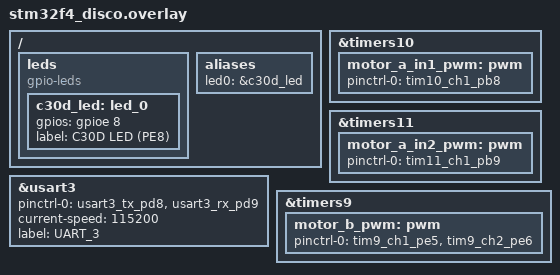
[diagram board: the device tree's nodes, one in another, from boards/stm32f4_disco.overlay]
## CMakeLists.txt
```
cmake_minimum_required(VERSION 3.20.0)

list(APPEND ZEPHYR_EXTRA_MODULES ${CMAKE_CURRENT_SOURCE_DIR}/../micro_ros_zephyr_module/modules/libmicroros)

find_package(Zephyr REQUIRED HINTS $ENV{ZEPHYR_BASE})
project(mdp_stm32_app)

target_sources(app PRIVATE
    src/main.c
    src/motor.c
)
```

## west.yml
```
manifest:
  remotes:
    - name: zephyrproject-rtos
      url-base: https://github.com/zephyrproject-rtos
    - name: micro-ROS
      url-base: https://github.com/micro-ROS

  projects:
    - name: zephyr
      remote: zephyrproject-rtos
      revision: v4.0.0
      import:
        name-allowlist:
          - cmsis          # ARM Cortex core headers
          - hal_stm32      # ST hardware abstraction (STM32F407 drivers/pinctrl/clock)
          - picolibc       # Small C library
          - segger         # SEGGER RTT debug print over ST-LINK
    - name: micro_ros_zephyr_module
      remote: micro-ROS
      revision: 229ffc0e131ee7942db3bb2e731fb8851583bb25

  self:
    path: .
```

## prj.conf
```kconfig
# GPIO & PWM Drivers
CONFIG_GPIO=y
CONFIG_PWM=y

# SEGGER RTT Console & Logging (Debug print via ST-LINK)
CONFIG_USE_SEGGER_RTT=y
CONFIG_RTT_CONSOLE=y
CONFIG_CONSOLE=y
CONFIG_LOG=y
CONFIG_LOG_BACKEND_RTT=y
CONFIG_LOG_MODE_IMMEDIATE=y

# Serial Drivers
CONFIG_SERIAL=y
CONFIG_UART_INTERRUPT_DRIVEN=y

# POSIX & Memory Defaults
CONFIG_POSIX_API=y
CONFIG_HEAP_MEM_POOL_SIZE=16384
CONFIG_MAIN_STACK_SIZE=4096
```

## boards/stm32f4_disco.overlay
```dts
/*
 * Devicetree overlay for WHEELTEC C30D (Revision 2.1) Control Board
 * Based on STM32F407VET6 MCU and AT8236 motor drivers.
 */

/ {
	leds {
		compatible = "gpio-leds";
		c30d_led: led_0 {
			gpios = <&gpioe 8 GPIO_ACTIVE_HIGH>;
			label = "C30D LED (PE8)";
		};
	};

	aliases {
		led0 = &c30d_led;
	};
};

/*
 * USART3 -> C30D USB-serial #3 (USB Type-C) on PD8 (TX3) and PD9 (RX3).
 * Connected via CH9102F USB-to-UART chip.
 */
&usart3 {
	pinctrl-0 = <&usart3_tx_pd8 &usart3_rx_pd9>;
	pinctrl-names = "default";
	current-speed = <115200>;
	status = "okay";
	label = "UART_3";
};

/*
 * AT8236 Dual H-Bridge Motor Drivers (PWM Output Timers)
 *
 * Motor A (Rear Left):  PB8 (TIM10_CH1) / PB9 (TIM11_CH1)
 * Motor B (Rear Right): PE5 (TIM9_CH1)  / PE6 (TIM9_CH2)
 * Motor C & D:          PE9, PE11, PE13, PE14 (TIM1)
 */
&timers10 {
	status = "okay";
	motor_a_in1_pwm: pwm {
		status = "okay";
		pinctrl-0 = <&tim10_ch1_pb8>;
		pinctrl-names = "default";
	};
};

&timers11 {
	status = "okay";
	motor_a_in2_pwm: pwm {
		status = "okay";
		pinctrl-0 = <&tim11_ch1_pb9>;
		pinctrl-names = "default";
	};
};

&timers9 {
	status = "okay";
	motor_b_pwm: pwm {
		status = "okay";
		pinctrl-0 = <&tim9_ch1_pe5 &tim9_ch2_pe6>;
		pinctrl-names = "default";
	};
};
```

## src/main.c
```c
#include <stdio.h>
#include <zephyr/kernel.h>
#include <zephyr/drivers/gpio.h>
#include <zephyr/sys/printk.h>
#include "motor.h"

static const struct gpio_dt_spec led = GPIO_DT_SPEC_GET(DT_ALIAS(led0), gpios);

int main(void)
{
	printk("=== STM32 C30D Board Bringup Test ===\n");

	if (!gpio_is_ready_dt(&led)) {
		printk("Error: LED GPIO device not ready\n");
		return 0;
	}

	int ret = gpio_pin_configure_dt(&led, GPIO_OUTPUT_ACTIVE);
	if (ret < 0) {
		printk("Error: Failed to configure LED GPIO pin\n");
		return 0;
	}

	if (motor_init() < 0) {
		printk("Error: AT8236 Motor PWM init failed\n");
		return 0;
	}

	printk("Success: LED & Motor PWM initialized cleanly!\n");

	while (1) {
		gpio_pin_toggle_dt(&led);

		/* Mirrored left/right motors need opposite signs for forward travel. */
		motor_set_speed(MOTOR_A, 0);
		motor_set_speed(MOTOR_B, 0);
		encoder_reset_counts();
		k_msleep(500);
	}

	return 0;
}
```

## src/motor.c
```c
#include "motor.h"

#include <zephyr/drivers/pwm.h>
#include <zephyr/sys/printk.h>

#define MOTOR_PWM_PERIOD_NS 50000

static const struct pwm_dt_spec motor_in1[MOTOR_COUNT] = {
	[MOTOR_A] = {.dev = DEVICE_DT_GET(DT_NODELABEL(motor_a_in1_pwm)),
		     .channel = 1,
		     .period = MOTOR_PWM_PERIOD_NS,
		     .flags = PWM_POLARITY_NORMAL},
	[MOTOR_B] = {.dev = DEVICE_DT_GET(DT_NODELABEL(motor_b_pwm)),
		     .channel = 1,
		     .period = MOTOR_PWM_PERIOD_NS,
		     .flags = PWM_POLARITY_NORMAL},
	[MOTOR_C] = {.dev = DEVICE_DT_GET(DT_NODELABEL(motor_cd_pwm)),
		     .channel = 1,
		     .period = MOTOR_PWM_PERIOD_NS,
		     .flags = PWM_POLARITY_NORMAL},
	[MOTOR_D] = {.dev = DEVICE_DT_GET(DT_NODELABEL(motor_cd_pwm)),
		     .channel = 3,
		     .period = MOTOR_PWM_PERIOD_NS,
		     .flags = PWM_POLARITY_NORMAL},
};

static const struct pwm_dt_spec motor_in2[MOTOR_COUNT] = {
	[MOTOR_A] = {.dev = DEVICE_DT_GET(DT_NODELABEL(motor_a_in2_pwm)),
		     .channel = 1,
		     .period = MOTOR_PWM_PERIOD_NS,
		     .flags = PWM_POLARITY_NORMAL},
	[MOTOR_B] = {.dev = DEVICE_DT_GET(DT_NODELABEL(motor_b_pwm)),
		     .channel = 2,
		     .period = MOTOR_PWM_PERIOD_NS,
		     .flags = PWM_POLARITY_NORMAL},
	[MOTOR_C] = {.dev = DEVICE_DT_GET(DT_NODELABEL(motor_cd_pwm)),
		     .channel = 2,
		     .period = MOTOR_PWM_PERIOD_NS,
		     .flags = PWM_POLARITY_NORMAL},
	[MOTOR_D] = {.dev = DEVICE_DT_GET(DT_NODELABEL(motor_cd_pwm)),
		     .channel = 4,
		     .period = MOTOR_PWM_PERIOD_NS,
		     .flags = PWM_POLARITY_NORMAL},
};

#define MOTOR_SPEED_MAX 1000

int motor_init(void)
{
	for (motor_id_t m = 0; m < MOTOR_COUNT; m++) {
		if (!pwm_is_ready_dt(&motor_in1[m]) || !pwm_is_ready_dt(&motor_in2[m])) {
			printk("motor: motor %d PWM device not ready\n", m);
			return -ENODEV;
		}
	}

	for (motor_id_t m = 0; m < MOTOR_COUNT; m++) {
		int rc = motor_set_speed(m, 0);
		if (rc < 0) {
			return rc;
		}
	}

	return 0;
}

int motor_set_speed(motor_id_t motor, int16_t speed)
{
	if (motor >= MOTOR_COUNT) {
		return -EINVAL;
	}

	if (speed > MOTOR_SPEED_MAX) {
		speed = MOTOR_SPEED_MAX;
	} else if (speed < -MOTOR_SPEED_MAX) {
		speed = -MOTOR_SPEED_MAX;
	}

	uint32_t in1_pulse = 0;
	uint32_t in2_pulse = 0;

	if (speed > 0) {
		in1_pulse = ((uint32_t)speed * motor_in1[motor].period) / MOTOR_SPEED_MAX;
	} else if (speed < 0) {
		in2_pulse = ((uint32_t)(-speed) * motor_in2[motor].period) / MOTOR_SPEED_MAX;
	}

	int rc = pwm_set_pulse_dt(&motor_in1[motor], in1_pulse);
	if (rc < 0) {
		return rc;
	}

	return pwm_set_pulse_dt(&motor_in2[motor], in2_pulse);
}
```

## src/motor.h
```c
#ifndef MOTOR_H_
#define MOTOR_H_

#include <stdint.h>

typedef enum {
	MOTOR_A = 0, /* Rear Left */
	MOTOR_B = 1, /* Rear Right */
	MOTOR_C = 2,
	MOTOR_D = 3,
	MOTOR_COUNT
} motor_id_t;

int motor_init(void);
int motor_set_speed(motor_id_t motor, int16_t speed);

#endif /* MOTOR_H_ */
```
